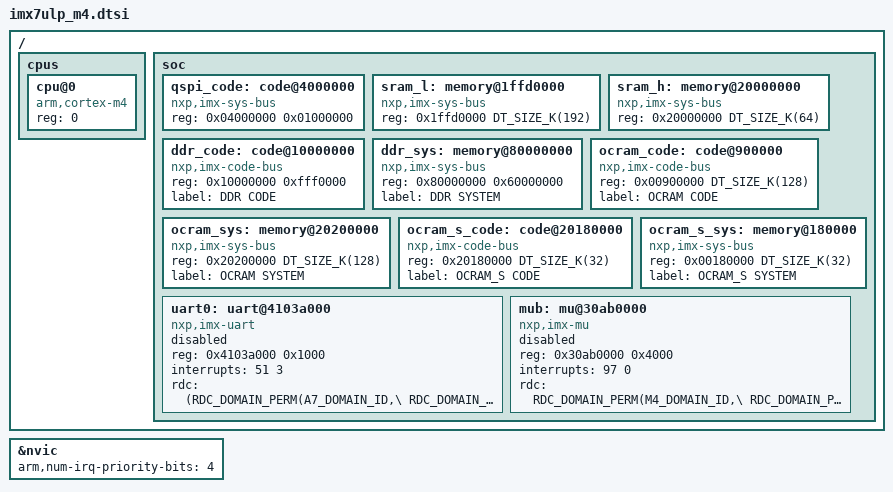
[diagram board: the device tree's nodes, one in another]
#include <mem.h>
#include <arm/armv7-m.dtsi>
#include <dt-bindings/rdc/imx_rdc.h>

/ {
	cpus {
		#address-cells = <1>;
		#size-cells = <0>;

		cpu@0 {
			device_type = "cpu";
			compatible = "arm,cortex-m4";
			reg = <0>;
		};
	};

	soc {

        qspi_code: code@4000000 {
			compatible = "nxp,imx-sys-bus";
			reg = <0x04000000 0x01000000>;
		};

        sram_l: memory@1ffd0000 {
			compatible = "nxp,imx-sys-bus";
			reg = <0x1ffd0000 DT_SIZE_K(192)>;
		};

        sram_h: memory@20000000 {
			compatible = "nxp,imx-sys-bus";
			reg = <0x20000000 DT_SIZE_K(64)>;
		};

		ddr_code: code@10000000 {
			compatible = "nxp,imx-code-bus";
			reg = <0x10000000 0xfff0000>;
			label = "DDR CODE";
		};

		ddr_sys: memory@80000000 {
			device_type = "memory";
			compatible = "nxp,imx-sys-bus";
			reg = <0x80000000 0x60000000>;
			label = "DDR SYSTEM";
		};

		ocram_code: code@900000 {
			compatible = "nxp,imx-code-bus";
			reg = <0x00900000 DT_SIZE_K(128)>;
			label = "OCRAM CODE";
		};

		ocram_sys: memory@20200000 {
			device_type = "memory";
			compatible = "nxp,imx-sys-bus";
			reg = <0x20200000 DT_SIZE_K(128)>;
			label = "OCRAM SYSTEM";
		};

		ocram_s_code: code@20180000 {
			compatible = "nxp,imx-code-bus";
			reg = <0x20180000 DT_SIZE_K(32)>;
			label = "OCRAM_S CODE";
		};

		ocram_s_sys: memory@180000 {
			device_type = "memory";
			compatible = "nxp,imx-sys-bus";
			reg = <0x00180000 DT_SIZE_K(32)>;
			label = "OCRAM_S SYSTEM";
		};

		uart0: uart@4103a000 {
			compatible = "nxp,imx-uart";
			reg = <0x4103a000 0x1000>;
			interrupts = <51 3>;
			rdc = <(RDC_DOMAIN_PERM(A7_DOMAIN_ID,\
					       RDC_DOMAIN_PERM_RW)|\
			       RDC_DOMAIN_PERM(M4_DOMAIN_ID,\
					       RDC_DOMAIN_PERM_RW))>;
			status = "disabled";
		};

		mub:mu@30ab0000 {
			compatible = "nxp,imx-mu";
			reg = <0x30ab0000 0x4000>;
			interrupts = <97 0>;
			rdc = <RDC_DOMAIN_PERM(M4_DOMAIN_ID,\
					       RDC_DOMAIN_PERM_RW)>;
			status = "disabled";
		};
	};
};

&nvic {
	arm,num-irq-priority-bits = <4>;
};
